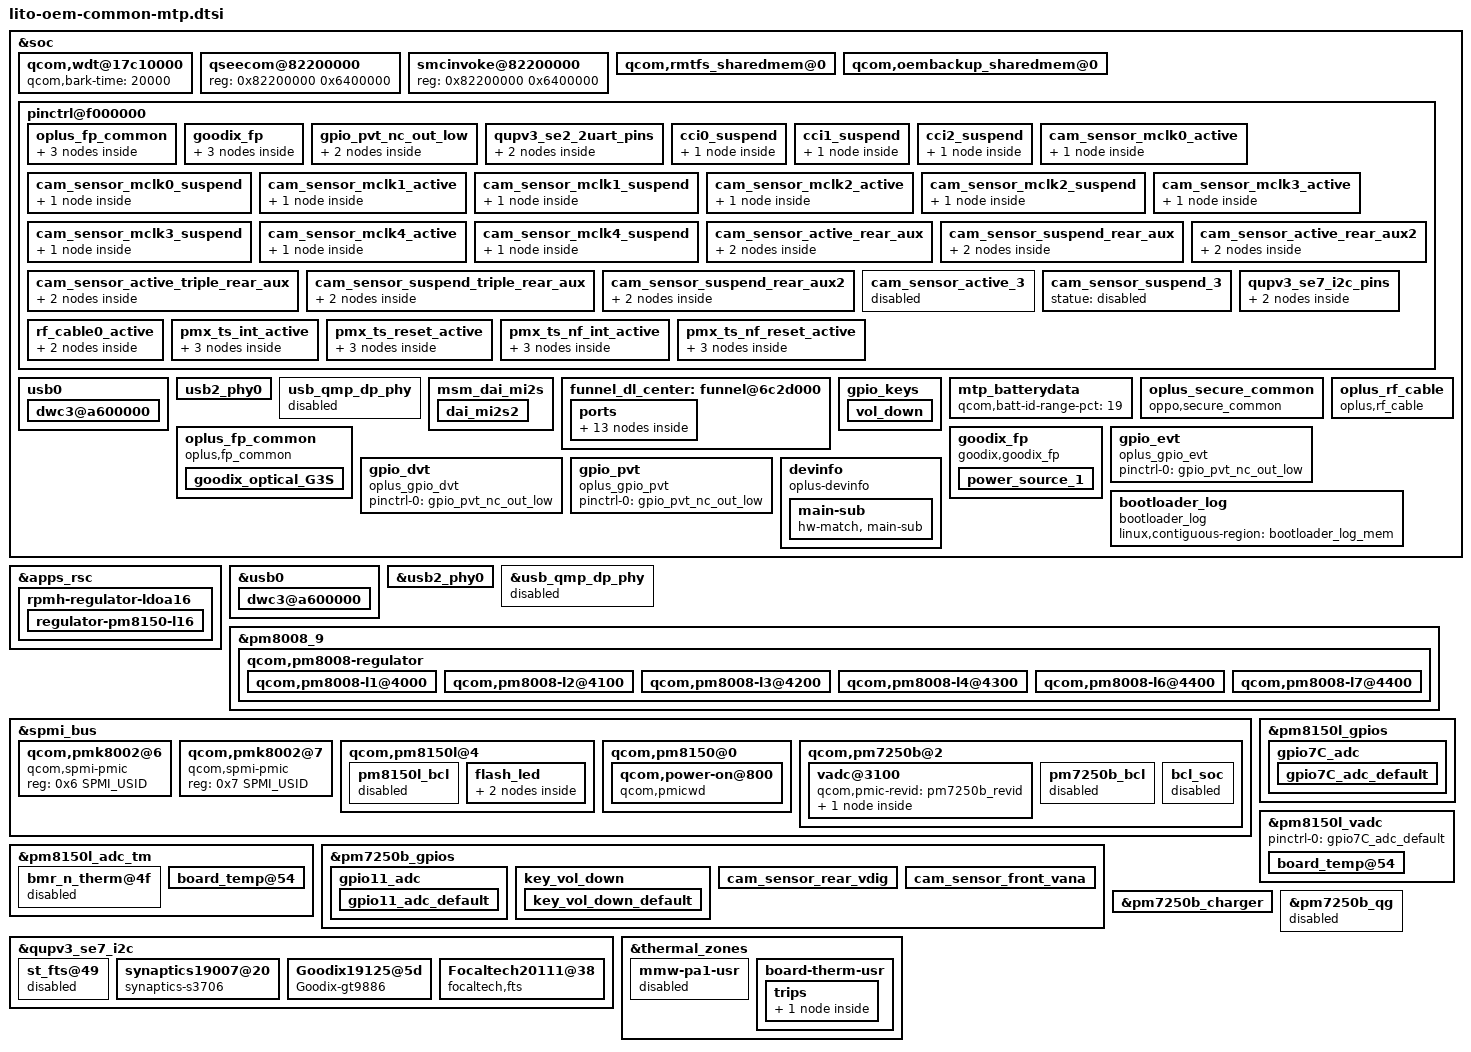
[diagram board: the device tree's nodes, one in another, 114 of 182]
// SPDX-License-Identifier: GPL-2.0-only
/*
 * Copyright (C) 2018-2020 Oplus. All rights reserved.
 */
#include <dt-bindings/msm/msm-bus-ids.h>
//#include "oplus_charge.dtsi"
#include "kunlun_camera/lito-camera-sensor-mtp.dtsi"
#include "display/lito-display.dtsi"

&soc {
        qcom,wdt@17c10000 {
               /*add for raising bark-time*/
               qcom,bark-time = <20000>;
        };
        qseecom@82200000 {
                //#ifndef OPLUS_FEATURE_FINGERPRINT
                //reg = <0x82200000 0x2200000>;
                //#else
                reg = <0x82200000 0x6400000>;
                //#endif /* OPLUS_FEATURE_FINGERPRINT */
        };

        smcinvoke@82200000 {
                //#ifndef OPLUS_FEATURE_FINGERPRINT
                //reg = <0x82200000 0x2200000>;
                //#else
                reg = <0x82200000 0x6400000>;
                //#endif /* OPLUS_FEATURE_FINGERPRINT */
        };

        qcom,rmtfs_sharedmem@0 {
                //#ifndef OPLUS_FEATURE_FINGERPRINT
                //reg = <0x0 0x200000>;
                //#else
                reg = <0x9ea00000 0x200000>;
                //#endif /* FEATURE_OPPO_NV_BACKUP */
                //#endif /* OPLUS_FEATURE_FINGERPRINT */

                //#ifdef VENDOR_EDIT
                //#ifdef FEATURE_OPPO_NV_BACKUP
                //add for oem share mem mapping virtual addr fail
                memory-region = <&uio_mem>;
                //#endif /* FEATURE_OPPO_NV_BACKUP */
                //#endif /* VENDOR_EDIT */
                qcom,guard-memory;
        };

        //#ifdef OPLUS_FEATURE_FINGERPRINT
        //#ifdef FEATURE_OPPO_NV_BACKUP
        //add for creating a shared memory with uio for nv backup and restore
        qcom,oembackup_sharedmem@0 {
                reg = <0x9ec00000 0x00100000>;
                memory-region = <&uio_oem>;
        };
        //#endif /* FEATURE_OPPO_NV_BACKUP */
        //#endif /* OPLUS_FEATURE_FINGERPRINT */

        pinctrl@f000000 {
        //#ifdef /*OPLUS_FEATURE_FINGERPRINT*/
        oplus_fp_common{
            gpio_id2_default: gpio_id2_default {
                mux {
                    pins = "gpio65";
                    function = "gpio";
                };
                config {
                    pins = "gpio65";
                    drive-strength = <2>;
                    bias-pull-up;
                    input-enable;
                };
            };
        };
        /*#ifdef OPLUS_FEATURE_FINGERPRINT Qijia.Zhou@Bsp.Fingerprint.Basic 2020-08-01 add for goodix fingerprint */
        goodix_fp{
            gpio_goodix_irq_default: gpio_goodix_irq_default {
                mux {
                    pins = "gpio112";
                    function = "gpio";
                };
                config {
                    pins = "gpio112";
                    drive-strength = <2>;
                    bias-disable;
                    input-enable;
                };
            };
        };
        //#endif /*OPLUS_FEATURE_FINGERPRINT*/

		gpio_pvt_nc_out_low: gpio_pvt_nc_out_low {
			mux {
				pins = "gpio48";
				function = "gpio";
			};

			config {
				pins = "gpio48";
				drive-strength = <2>;
				output-low;
			};

		};

                qupv3_se2_2uart_pins {
                        qupv3_se2_2uart_sleep {
                                config {
                                        input-enable;
                                        bias-disable;
                                        //#else
                                        ///bias-pull-down;
                                        //#endif
                                };
                        };
                };

                cci0_suspend {
                        config {
/*#ifdef VENDOR_EDIT */
                                //bias-pull-down; /* PULL DOWN */
                                bias-disable;
                                output-low;
/*endif*/
                        };
                };

                cci1_suspend {
                        config {
/*#ifdef VENDOR_EDIT */
                                //bias-pull-down; /* PULL DOWN */
                                bias-disable;
                                output-low;
/*endif*/
                        };
                };

                cci2_suspend {
                        config {
/*#ifdef VENDOR_EDIT */
                                //bias-pull-down; /* PULL DOWN */
                                bias-disable;
                                output-low;
/*endif*/
                        };
                };

                /* Camera GPIOs  CCI*/
                cam_sensor_mclk0_active {
                        config {
/*#ifdef VENDOR_EDIT */
                                drive-strength = <6>; /* 2 MA */
/*endif*/
                        };
                };

                cam_sensor_mclk0_suspend {
                        config {
/*#ifdef VENDOR_EDIT */
                                drive-strength = <6>; /* 2 MA */
/*endif*/
                        };
                };

                cam_sensor_mclk1_active {
                        config {
/*#ifdef VENDOR_EDIT */
                                drive-strength = <6>; /* 2 MA */
/*endif*/
                        };
                };

                cam_sensor_mclk1_suspend {
                        config {
/*#ifdef VENDOR_EDIT */
                                drive-strength = <6>; /* 2 MA */
/*endif*/
                        };
                };

                cam_sensor_mclk2_active {
                        config {
/*#ifdef VENDOR_EDIT */
                                drive-strength = <4>; /* 2 MA */
/*endif*/
                        };
                };

                cam_sensor_mclk2_suspend {
                        config {
/*#ifdef VENDOR_EDIT */
                                drive-strength = <4>; /* 2 MA */
/*endif*/
                        };
                };

                cam_sensor_mclk3_active {
                        config {
/*#ifdef VENDOR_EDIT */
                                drive-strength = <6>; /* 2 MA */
/*endif*/
                        };
                };

                cam_sensor_mclk3_suspend {
                        config {
/*#ifdef VENDOR_EDIT */
                                drive-strength = <6>; /* 2 MA */
/*endif*/
                        };
                };

                cam_sensor_mclk4_active {
                        config {
/*#ifdef VENDOR_EDIT */
                                drive-strength = <6>; /* 2 MA */
/*endif*/
                        };
                };

                cam_sensor_mclk4_suspend {
                        config {
/*#ifdef VENDOR_EDIT */
                                drive-strength = <6>; /* 2 MA */
/*endif*/
                        };
                };

                cam_sensor_active_rear_aux {
                        /* RESET REARAUX,DVDD ELDO */
                        mux {
                                pins = "gpio21";
                        };

                        config {
                                pins = "gpio21";
                        };
                };

                cam_sensor_suspend_rear_aux {
                        /* RESET REARAUX,DVDD ELDO */
                        mux {
                                pins = "gpio21";
                        };

                        config {
                                pins = "gpio21";
                        };
                };

                cam_sensor_active_triple_rear_aux {
                        mux {
                                pins = "gpio23";
                        };

                        config {
                                pins = "gpio23";
                        };
                };

                cam_sensor_suspend_triple_rear_aux {
                        mux {
                                pins = "gpio23";
                        };

                        config {
                                pins = "gpio23";
                        };
                };

                cam_sensor_active_rear_aux2 {
                        mux {
                                pins = "gpio29";
                        };

                        config {
                                pins = "gpio29";
                        };
                };

                cam_sensor_suspend_rear_aux2 {
                        mux {
                                pins = "gpio29";
                        };

                        config {
                                pins = "gpio29";
                        };
                };

                cam_sensor_active_3 {
                        status = "disabled";
                };

                cam_sensor_suspend_3 {
                        statue = "disabled";
                };

                /* SE 7 pin mappings */
                qupv3_se7_i2c_pins {
                        qupv3_se7_i2c_sleep {
                                config {
                                        //#ifdef VENDOR_EDIT
                                        //Zengpeng.Chen@BSP.TP.Function 2019-08-08 add for set i2c bus line as input
                                        input-enable;
                                        //#endif//VENDOR_EDIT
                                };
                        };
                };

		//#ifdef VENDOR_EDIT
		/* Fuchun.Liao@BSP.CHG.Basic 2018/11/27 modify for rf-cable */
		rf_cable0_active: rf_cable0_active {
			mux {
				pins = "gpio90";
				function = "gpio";
			};
			config {
				pins = "gpio90";
				drive-strength = <2>;
				input-enable;
				bias-pull-up;
			};
		};
		//#endif /* VENDOR_EDIT */ 

                //#ifdef VENDOR_EDIT
                pmx_ts_int_active {
                        ts_int_active: ts_int_active {
                                mux {
                                        pins = "gpio9";
                                        function = "gpio";
                                };

                                config {
                                        pins = "gpio9";
                                        drive-strength = <2>;
                                        bias-disable;
                                };
                        };
                };

                pmx_ts_reset_active {
                        ts_reset_active: ts_reset_active {
                                mux {
                                        pins = "gpio8";
                                        function = "gpio";
                                };

                                config {
                                        pins = "gpio8";
                                        drive-strength = <2>;
                                        bias-disable;
                                        output-low;
                                };
                        };
                };

                pmx_ts_nf_int_active {
                        ts_nf_int_active: ts_nf_int_active {
                                mux {
                                        pins = "gpio5";
                                        function = "gpio";
                                };

                                config {
                                        pins = "gpio5";
                                        drive-strength = <2>;
                                        bias-disable;
                                };
                        };
                };

                pmx_ts_nf_reset_active {
                        ts_nf_reset_active: ts_nf_reset_active {
                                mux {
                                        pins = "gpio4";
                                        function = "gpio";
                                };

                                config {
                                        pins = "gpio4";
                                        drive-strength = <2>;
                                        bias-disable;
                                        output-low;
                                };
                        };
                };
                //#endif
        };
};

&apps_rsc {
	rpmh-regulator-ldoa16 {
		regulator-pm8150-l16 {
			//#ifdef VENDOR_EDIT
			//LiPing-m@PSW.MM.Display.LCD 2018-10-21 Modity for lcd
			regulator-min-microvolt = <3000000>;
			qcom,init-voltage = <3000000>;
			//#endif
		};
	};
};

&soc {
        usb0 {
//#ifndef OPLUS_FEATRUE_CHG_BASIC
//Kun.Zhang@BSP.CHG.Basic  2019/11/22  Modify for mtp/otg speed 
                //qcom,core-clk-rate = <133333333>;
//#else
                qcom,core-clk-rate = <200000000>;
//#endif

                qcom,msm-bus,vectors-KBps =
                        /*  suspend vote */
                        <MSM_BUS_MASTER_USB3 MSM_BUS_SLAVE_EBI_CH0 0 0>,
                        <MSM_BUS_MASTER_USB3 MSM_BUS_SLAVE_IPA_CFG 0 0>,
                        <MSM_BUS_MASTER_AMPSS_M0 MSM_BUS_SLAVE_USB3 0 0>,

                        /*  nominal vote */
//#ifndef OPLUS_FEATRUE_CHG_BASIC
//Kun.Zhang@BSP.CHG.Basic  2019/11/22  Modify for mtp/otg speed 
                        //<MSM_BUS_MASTER_USB3
                                //MSM_BUS_SLAVE_EBI_CH0 1000000 2500000>,
                        //<MSM_BUS_MASTER_USB3 MSM_BUS_SLAVE_IPA_CFG 0 2400>,
                        //<MSM_BUS_MASTER_AMPSS_M0 MSM_BUS_SLAVE_USB3 0 40000>,
//#else
                        <MSM_BUS_MASTER_USB3
                                MSM_BUS_SLAVE_EBI_CH0 2500000 2500000>,
                        <MSM_BUS_MASTER_USB3 MSM_BUS_SLAVE_IPA_CFG 2400 2400>,
                        <MSM_BUS_MASTER_AMPSS_M0 MSM_BUS_SLAVE_USB3 40000 40000>,
//#endif

                        /*  svs vote */
//#ifndef OPLUS_FEATRUE_CHG_BASIC
//Kun.Zhang@BSP.CHG.Basic  2019/11/22  Modify for mtp/otg speed 
                        //<MSM_BUS_MASTER_USB3
                                //MSM_BUS_SLAVE_EBI_CH0 240000 700000>,
                        //<MSM_BUS_MASTER_USB3 MSM_BUS_SLAVE_IPA_CFG 0 2400>,
                        //<MSM_BUS_MASTER_AMPSS_M0 MSM_BUS_SLAVE_USB3 0 40000>,
//#else
                        <MSM_BUS_MASTER_USB3
                                MSM_BUS_SLAVE_EBI_CH0 2500000 2500000>,
                        <MSM_BUS_MASTER_USB3 MSM_BUS_SLAVE_IPA_CFG 2400 2400>,
                        <MSM_BUS_MASTER_AMPSS_M0 MSM_BUS_SLAVE_USB3 40000 40000>,
//#endif

                        /*  min vote */
                        <MSM_BUS_MASTER_USB3 MSM_BUS_SLAVE_EBI_CH0 1 1>,
                        <MSM_BUS_MASTER_USB3 MSM_BUS_SLAVE_IPA_CFG 1 1>,
                        <MSM_BUS_MASTER_AMPSS_M0 MSM_BUS_SLAVE_USB3 1 1>;

                dwc3@a600000 {
//#ifndef OPLUS_FEATRUE_CHG_BASIC
//Kun.Zhang@BSP.CHG.Basic  2019/09/25  Delete for usb 2.0
                        //usb-phy = <&usb2_phy0>, <&usb_qmp_dp_phy>;
//#else
                        usb-phy = <&usb2_phy0>, <&usb_nop_phy>;
//#endif

//#ifdef OPLUS_FEATRUE_CHG_BASIC
//Kun.Zhang@BSP.CHG.Basic  2019/11/22  add for mtp/otg speed 
                        xhci-imod-value = <160>;
                        qcom,pm-qos-latency= <62>;
//#endif

//#ifndef OPLUS_FEATRUE_CHG_BASIC
//Kun.Zhang@BSP.CHG.Basic  2019/09/25  Modify for usb 2.0
                        //maximum-speed = "super-speed";
//#else
                        maximum-speed = "high-speed";
//#endif
                };
        };

        usb2_phy0 {
//#ifndef OPLUS_FEATRUE_CHG_BASIC
//Kun.Zhang@BSP.CHG.Basic  2019/09/25  Delete for usb eye parameter
                //qcom,param-override-seq = <0x43 0x70>;
//#else
                qcom,param-override-seq = <0x07 0x6c
                                                                  0x0b 0x70
                                                                  0x04 0x74
                                                                  0x00 0x78>;
//#ifdef OPLUS_FEATRUE_CHG_BASIC
//Jacky.Zhuo@BSP.CHG.Basic  2020/04/27  Add for host mode eye diagram
                qcom,param-override-seq-host = <0x07 0x6c
                                                                  0x0b 0x70
                                                                  0x04 0x74
                                                                  0x00 0x78>;
//#endif
//#endif
        };

        usb_qmp_dp_phy {
//#ifndef OPLUS_FEATRUE_CHG_BASIC
//Kun.Zhang@BSP.CHG.Basic  2019/09/25  Modify for usb 2.0
                //status = "ok";
//#else
                status = "disabled";
//endif
        };
};

&usb0 {
//#ifndef OPLUS_FEATRUE_CHG_BASIC
//Kun.Zhang@BSP.CHG.Basic  2019/11/22  Modify for mtp/otg speed 
                //qcom,core-clk-rate = <133333333>;
//#else
                qcom,core-clk-rate = <200000000>;
//#endif

                qcom,msm-bus,vectors-KBps =
                        /*  suspend vote */
                        <MSM_BUS_MASTER_USB3 MSM_BUS_SLAVE_EBI_CH0 0 0>,
                        <MSM_BUS_MASTER_USB3 MSM_BUS_SLAVE_IPA_CFG 0 0>,
                        <MSM_BUS_MASTER_AMPSS_M0 MSM_BUS_SLAVE_USB3 0 0>,

                        /*  nominal vote */
//#ifndef OPLUS_FEATRUE_CHG_BASIC
//Kun.Zhang@BSP.CHG.Basic  2019/11/22  Modify for mtp/otg speed 
                        //<MSM_BUS_MASTER_USB3
                                //MSM_BUS_SLAVE_EBI_CH0 1000000 2500000>,
                        //<MSM_BUS_MASTER_USB3 MSM_BUS_SLAVE_IPA_CFG 0 2400>,
                        //<MSM_BUS_MASTER_AMPSS_M0 MSM_BUS_SLAVE_USB3 0 40000>,
//#else
                        <MSM_BUS_MASTER_USB3
                                MSM_BUS_SLAVE_EBI_CH0 2500000 2500000>,
                        <MSM_BUS_MASTER_USB3 MSM_BUS_SLAVE_IPA_CFG 2400 2400>,
                        <MSM_BUS_MASTER_AMPSS_M0 MSM_BUS_SLAVE_USB3 40000 40000>,
//#endif

                        /*  svs vote */
//#ifndef OPLUS_FEATRUE_CHG_BASIC
//Kun.Zhang@BSP.CHG.Basic  2019/11/22  Modify for mtp/otg speed 
                        //<MSM_BUS_MASTER_USB3
                                //MSM_BUS_SLAVE_EBI_CH0 240000 700000>,
                        //<MSM_BUS_MASTER_USB3 MSM_BUS_SLAVE_IPA_CFG 0 2400>,
                        //<MSM_BUS_MASTER_AMPSS_M0 MSM_BUS_SLAVE_USB3 0 40000>,
//#else
                        <MSM_BUS_MASTER_USB3
                                MSM_BUS_SLAVE_EBI_CH0 2500000 2500000>,
                        <MSM_BUS_MASTER_USB3 MSM_BUS_SLAVE_IPA_CFG 2400 2400>,
                        <MSM_BUS_MASTER_AMPSS_M0 MSM_BUS_SLAVE_USB3 40000 40000>,
//#endif

                        /*  min vote */
                        <MSM_BUS_MASTER_USB3 MSM_BUS_SLAVE_EBI_CH0 1 1>,
                        <MSM_BUS_MASTER_USB3 MSM_BUS_SLAVE_IPA_CFG 1 1>,
                        <MSM_BUS_MASTER_AMPSS_M0 MSM_BUS_SLAVE_USB3 1 1>;

                dwc3@a600000 {
//#ifndef OPLUS_FEATRUE_CHG_BASIC
//Kun.Zhang@BSP.CHG.Basic  2019/09/25  Delete for usb 2.0
                        //usb-phy = <&usb2_phy0>, <&usb_qmp_dp_phy>;
//#else
                        usb-phy = <&usb2_phy0>, <&usb_nop_phy>;
//#endif

//#ifdef OPLUS_FEATRUE_CHG_BASIC
//Kun.Zhang@BSP.CHG.Basic  2019/11/22  add for mtp/otg speed 
                        xhci-imod-value = <160>;
                        qcom,pm-qos-latency= <62>;
//#endif

//#ifndef OPLUS_FEATRUE_CHG_BASIC
//Kun.Zhang@BSP.CHG.Basic  2019/09/25  Modify for usb 2.0
                        //maximum-speed = "super-speed";
//#else
                        maximum-speed = "high-speed";
//#endif
                };
};
&usb2_phy0 {
//#ifndef OPLUS_FEATRUE_CHG_BASIC
//Kun.Zhang@BSP.CHG.Basic  2019/09/25  Delete for usb eye parameter
                //qcom,param-override-seq = <0x43 0x70>;
//#else
                qcom,param-override-seq = <0x07 0x6c
                                                                  0x0b 0x70
                                                                  0x04 0x74
                                                                  0x00 0x78>;
//#ifdef OPLUS_FEATRUE_CHG_BASIC
//Jacky.Zhuo@BSP.CHG.Basic  2020/04/27  Add for host mode eye diagram
                qcom,param-override-seq-host = <0x07 0x6c
                                                                  0x0b 0x70
                                                                  0x04 0x74
                                                                  0x00 0x78>;
//#endif
//#endif
};

&usb_qmp_dp_phy {
//#ifndef OPLUS_FEATRUE_CHG_BASIC
//Kun.Zhang@BSP.CHG.Basic  2019/09/25  Modify for usb 2.0
                //status = "ok";
//#else
                status = "disabled";
//endif
};
&soc {
	msm_dai_mi2s {
		dai_mi2s2 {
			qcom,msm-mi2s-rx-lines = <0>;
			qcom,msm-mi2s-tx-lines = <3>;
		};
	};
};

&soc {
	funnel_dl_center: funnel@6c2d000 {
		ports {
			port@1 {
				reg = <0>;
			};

			port@2 {
				reg = <0>;
			};

			port@3 {
				reg = <0>;
			};

			port@4 {
				reg = <0>;
			};

			port@5 {
				reg = <0>;
			};

			port@6 {
				reg = <0>;
			};

			port@7 {
				reg = <0>;
			};

			port@8 {
				reg = <0>;
			};

			port@9 {
				reg = <0>;
			};

			port@10 {
				reg = <0>;
			};

			port@11 {
				reg = <0>;
			};

			port@12 {
				reg = <0>;
			};

			port@13 {
				reg = <0>;
			};
		};
	};
};

&pm8008_9 {
	qcom,pm8008-regulator {
		vdd_l5-supply = <&S5A>;
		vdd_l6-supply = <&BOB>;
		vdd_l7-supply = <&BOB>;

		qcom,pm8008-l1@4000 {
			reg =  /bits/ 16 <0x4000>;
		/*#ifdef VENDOR_EDIT */
		        regulator-min-microvolt = <950000>;
		        regulator-max-microvolt = <1150000>;
		        qcom,min-dropout-voltage = <100000>;
		/*endif */
		};

		qcom,pm8008-l2@4100 {
			reg =  /bits/ 16 <0x4100>;
		/*#ifdef VENDOR_EDIT */
		        regulator-min-microvolt = <1200000>;
		        regulator-max-microvolt = <1200000>;
		        qcom,min-dropout-voltage = <100000>;
		/*endif */
		};

		qcom,pm8008-l3@4200 {
			reg =  /bits/ 16 <0x4200>;
		        regulator-min-microvolt = <2800000>;
		        regulator-max-microvolt = <2800000>;
		/*#ifdef VENDOR_EDIT */
		        //qcom,min-dropout-voltage = <136000>;
		/*endif */
		};

		qcom,pm8008-l4@4300 {
			reg =  /bits/ 16 <0x4300>;
		/*#ifdef VENDOR_EDIT */
		        regulator-max-microvolt = <2800000>;
		        //qcom,min-dropout-voltage = <160000>;
		/*endif */
		};

		qcom,pm8008-l6@4400 {
			reg =  /bits/ 16 <0x4500>;
		/*#ifdef VENDOR_EDIT */
		        regulator-min-microvolt = <2800000>;
		        regulator-max-microvolt = <2800000>;
		        //qcom,min-dropout-voltage = <184000>;
		/*endif */
		};

		qcom,pm8008-l7@4400 {
			reg =  /bits/ 16 <0x4600>;
		/*#ifdef VENDOR_EDIT */
		        regulator-min-microvolt = <2900000>;
		        regulator-max-microvolt = <2900000>;
		        //qcom,min-dropout-voltage = <200000>;
		/*endif */
		};
	};
};

&spmi_bus {
	/*Add spmi node for clk pmic PMK8002 */
	qcom,pmk8002@6 {
		compatible ="qcom,spmi-pmic";
		reg = <0x6 SPMI_USID>;
		#address-cells = <2>;
		#size-cells = <0>;
	};

	qcom,pmk8002@7 {
	compatible ="qcom,spmi-pmic";
		reg = <0x7 SPMI_USID>;
		#address-cells = <2>;
		#size-cells = <0>;
	};

	qcom,pm8150l@4 {
		pm8150l_bcl {
//#ifdef VENDOR_EDIT
//Kun.Zhang@BSP.CHG.Basic  2019/12/27  Modify for disable bcl 
			status = "disabled";
//#endif
		};

		flash_led {
			pm8150l_flash2 {
				/*#ifdef VENDOR_EDIT */
				status = "ok";
				/*endif */
			};

			pm8150l_torch2 {
				/*#ifdef VENDOR_EDIT */
				status = "ok";
				/*endif */
			};
		};
	};
	qcom,pm8150@0 {
		qcom,power-on@800
		{
			//#ifdef CONFIG_OPLUS_FEATURE_QCOM_PMICWD
			qcom,pmicwd;
			//#endif
		};
	};
};

&spmi_bus {
        qcom,pm7250b@2 {
                vadc@3100 {
                        //#ifdef VENDOR_EDIT
                        qcom,pmic-revid = <&pm7250b_revid>;
                        //#endif
			board_id {
				reg = <ADC_GPIO1>;
				label = "board_id_vdata";
				qcom,ratiometric;
				qcom,pre-scaling = <1 1>;
			}; 
                };

                pm7250b_bcl {
//#ifdef VENDOR_EDIT
//Kun.Zhang@BSP.CHG.Basic  2019/12/27  Modify for disable bcl 
                        status = "disabled";
//#endif
                };

                bcl_soc {
//#ifdef VENDOR_EDIT
//Kun.Zhang@BSP.CHG.Basic  2019/12/27  Modify for disable bcl 
                        status = "disabled";
//#endif
                };
        };
};

&soc {
	gpio_keys {
		//#ifdef VENDOR_EDIT
		//Fei.Mo@BSP.group 2018-09-01 Modity for vol key
		pinctrl-0 = <&key_vol_up_default &key_vol_down_default>;
		//#endif

		//#ifdef VENDOR_EDIT
		//Fei.Mo@BSP.group 2018-09-01 Add for vol key
		vol_down {
			label = "volume_down";
			gpios = <&pm7250b_gpios  3 GPIO_ACTIVE_LOW>;
			linux,input-type = <1>;
			linux,code = <KEY_VOLUMEDOWN>;
			gpio-key,wakeup;
			debounce-interval = <15>;
			linux,can-disable;
		};
		//#endif
	};

        mtp_batterydata {
//#ifndef VENDOR_EDIT
//Yichun.Chen@BSP.CHG.Basic  2018/05/10  Delete for use oppo battery
//              qcom,batt-id-range-pct = <15>;
//#else
        qcom,batt-id-range-pct = <19>;
//#endif
        };

        // #ifdef OPLUS_FEATURE_SECURITY_COMMON
        /* Ping.Liu@Bsp.Fingerprint.Secure 2019-10-16 add for secure proc */
        oplus_secure_common {
                compatible = "oppo,secure_common";
        };
        //#endif /* OPLUS_FEATURE_SECURITY_COMMON */

    //#ifdef OPLUS_FEATURE_FINGERPRINT /*OPLUS_FEATURE_FINGERPRINT*/
    oplus_fp_common {
        compatible = "oplus,fp_common";
        oplus,fp_gpio_num = <1>; /* the gpio number of fingerprint id used */
        oplus,fp_gpio_0 = <&tlmm 65 0x0>;
        pinctrl-names = "default";
        pinctrl-0 = <&gpio_id2_default>;
        goodix_optical_G3S {
            oplus,fp-id = <1>; /* fp id mapping table */
            vendor-chip = <11>; /* please refer to the struct fp_vendor_t in oppo_fp_commmon.n */
            eng-menu = "-1,-1"; /* represents SNR, inclination test item in engineer menu, and 0/1 means off/on */
            chip-name = "G_OPTICAL_G3S";  /* /proc/fp_id, will be displayed in engineer menu  */
        };
    };

    goodix_fp {
        status = "ok";
        compatible = "goodix,goodix_fp";
        interrupt-parent = <&tlmm>;
        interrupts = <112 0>;
        power-mode = <1> ; /*please refer to the struct fp_power_mode_t in oppo_fp_commmon.n ,0: power mode not set, 1: ldo power, 2: gpio power, 3: auto power */
        ldo-supply = <&pm8150a_l9>; // pm660l_l5 for goodix_fp
        ldo-config = <3300000 3300000 150000>;
        gpio-power = <&pm8150_gpios 7 GPIO_ACTIVE_LOW>;
        goodix,gpio_irq = <&tlmm 112 0x1>;
        goodix,gpio_reset = <&tlmm 63 0x0>;
        pinctrl-names = "default";
        pinctrl-0 = <&gpio_goodix_irq_default>;
        notify_tpinfo_flag = <1>;
        power-num = <1> ;
        power_source_1 {
            power-mode = <1>;   /* 1 = ldo power, refer to oplus_fp_common.h*/
            power-name = "ldo";
            power-config = "ldo-config";
            delay-time = <0>;
        };
    };
    //#endif /*OPLUS_FEATURE_FINGERPRINT*/

	gpio_evt {
		status = "ok";
		compatible = "oplus_gpio_evt";
		pinctrl-names = "default";
		pinctrl-0 = <&gpio_pvt_nc_out_low>;
	};
	//#endif
	gpio_dvt {
		status = "ok";
		compatible = "oplus_gpio_dvt";
		pinctrl-names = "default";
		pinctrl-0 = <&gpio_pvt_nc_out_low>;
	};
	gpio_pvt {
		status = "ok";
		compatible = "oplus_gpio_pvt";
		pinctrl-names = "default";
		pinctrl-0 = <&gpio_pvt_nc_out_low>;
	};

	devinfo {
		compatible = "oplus-devinfo";

		io-channels= <&pm7250b_vadc ADC_GPIO1>;
		io-channel-names= "vph_pwr_voltage_sub";
		pinctrl-names = "default";
		pinctrl-0 = <&gpio11_adc_default>;

		main-sub {
			compatible = "hw-match, main-sub";
			use_pmic_adc;
			adc_ranges = <0 80
						81 180
						181 300
						301 420
						421 550
						551 650
						651 760
						761 850
						851 850
						951 1050
						1051 1150
						1151 1300>;
			aboard-patterns = <0 0 1>;

			/*main board*/
			match-projects = <20111 20113 20251 20811>;
		};
	};

	/* Fuchun.Liao@BSP.CHG.Basic 2018/11/26 modify for oplus rf cable monitor */
        oplus_rf_cable {
                compatible = "oplus,rf_cable";
                interrupt-parent = <&tlmm>;
                rf_cable_support_num = <1>;
                rf,cable0-gpio = <&tlmm 90 0>;
                rf,cable-support-timer = <0>;
                pinctrl-names = "rf_cable_active";
                pinctrl-0 = <&rf_cable0_active>;
        };
	//#endif /* VENDOR_EDIT */
};

&pm8150l_gpios {
/*#ifdef OPLUS_FEATURE_BOARD_TEMP */
        gpio7C_adc {
			gpio7C_adc_default: gpio7C_adc_default {
			pins = "gpio7"; /* GPIO07 */
			function = "normal"; /* normal */
			bias-high-impedance; /* DISABLE GPIO07 for ADC*/
			bias-disable;
		};
	};

/*#endif*/
};

&pm8150l_vadc {
/*#ifdef OPLUS_FEATURE_BOARD_TEMP */
	pinctrl-names = "default";
	pinctrl-0 = <&gpio7C_adc_default>;
/*#endif*/

/*#ifdef OPLUS_FEATURE_BOARD_TEMP */
	board_temp@54 {
		reg = <ADC_GPIO3_PU2>;
		label = "board_temp";
		qcom,ratiometric;
		qcom,hw-settle-time = <200>;
		qcom,pre-scaling = <1 1>;
	};
/*#endif*/
};

&pm8150l_adc_tm {
	io-channels = <&pm8150l_vadc ADC_AMUX_THM1_PU2>,
			<&pm8150l_vadc ADC_AMUX_THM2_PU2>,
			<&pm8150l_vadc ADC_AMUX_THM3_PU2>,
/*#ifdef OPLUS_FEATURE_BOARD_TEMP */
			<&pm8150l_vadc ADC_GPIO3_PU2>;
/*#endif*/

/*#ifndef OPLUS_FEATURE_BOARD_TEMP */
	bmr_n_therm@4f {
		status = "disabled";
	};
/*#endif*/
/*#ifdef OPLUS_FEATURE_BOARD_TEMP */
	board_temp@54 {
		reg = <ADC_GPIO3_PU2>; //PM7150A_GPIO7
		qcom,ratiometric;
		qcom,hw-settle-time = <200>;
	};
/*#endif*/
};

&pm7250b_gpios{
//#ifdef VENDOR_EDIT
//tongfeng.huang@BSP.CHG.Basic  2019/11/20  add for board-id adc
        gpio11_adc {
        gpio11_adc_default: gpio11_adc_default {
        pins = "gpio11"; /* GPIO 11 */
        function = "normal"; /* normal */
        bias-high-impedance; /* DISABLE GPIO11 for ADC*/
        };
    };
//#endif

	//#ifdef VENDOR_EDIT
	//Fei.Mo@BSP.group 2018-09-01 Add for vol key
	key_vol_down {
		key_vol_down_default: key_vol_down_default {
			pins = "gpio3";
			function = "normal";
			input-enable;
			bias-pull-up;
			power-source = <0>;
		};
	};
	//#endif

/*#ifdef VENDOR_EDIT */
	cam_sensor_rear_vdig: cam_sensor_rear_vdig {
		pins = "gpio10";
		function = "normal";
		power-source = <0>;
		drive-push-pull;
		output-low;
	};
	cam_sensor_front_vana: cam_sensor_front_vana {
		pins = "gpio12";
		function = "normal";
		power-source = <0>;
		drive-push-pull;
		output-low;
	};
/*
	cam_sensor_rear2_vana: cam_sensor_rear2_vana {
		pins = "gpio2";
		function = "normal";
		power-source = <0>;
		output-low;
	};

*/
/*endif */
};

&pm7250b_charger {
        io-channels = <&pm7250b_vadc ADC_USB_IN_V_16>,
                      <&pm7250b_vadc ADC_USB_IN_I>,
                      <&pm7250b_vadc ADC_CHG_TEMP>,
                          <&pm7250b_vadc ADC_GPIO3>,
                          <&pm7250b_vadc ADC_AMUX_THM4_PU2>,
//#endif
                      <&pm7250b_vadc ADC_DIE_TEMP>,
                      <&pm7250b_vadc ADC_AMUX_THM3_PU2>,
                      <&pm7250b_vadc ADC_SBUx>,
                      <&pm7250b_vadc ADC_VPH_PWR>,
                      <&pm7250b_vadc ADC_AMUX_THM1_PU2>;
        io-channel-names = "usb_in_voltage",
                           "usb_in_current",
                           "chg_temp",
                           "chgID_voltage_adc",
                           "usb_temp_l",
//#endif
                           "die_temp",
                           "usb_temp_r",
//#else
                           //"conn_temp",
//#endif
                           "sbux_res",
                           "vph_voltage",
                           "skin_temp";
};

&pm7250b_qg {
        status = "disabled";
//#else
        //status = "ok";
//#endif
};

&qupv3_se7_i2c {
        //#ifdef VENDOR_EDIT
        //wangkun@BSP.group 2019-06-28 add for enable i2c_7
	st_fts@49 {
		status = "disabled";
	};

        synaptics19007@20 {
                compatible = "synaptics-s3706";
                reg = <0x20>;
                chip-name = "S3706";

                /* Interrupt && Irq-gpio */
                interrupt-parent = <&tlmm>;
                interrupts = <9 0x2008>;

                /* Power Config */
                vdd_2v8-supply = <&pm8150_l13>;
                vcc_1v8-supply = <&pm8150a_l1>;
                vdd_2v8_volt = <3000000>;

                /* Other HW Resource */
                irq-gpio = <&tlmm 9 0x2008>;
                reset-gpio = <&tlmm 8 0x1>;
                pinctrl-names = "default";
                pinctrl-0 = <&ts_int_active &ts_reset_active>;

                touchpanel,max-num-support = <10>;
                touchpanel,tx-rx-num = <16 34>;
                touchpanel,panel-coords = <1080 2340>;
                touchpanel,display-coords = <1080 2340>;
                touchpanel,touchmajor-limit = <0 54>;

                /* SW Support Feature Control */
                black_gesture_support;
                fw_edge_limit_support;
                fw_corner_limit_support;
                pressure_report_support;
                //spurious_fingerprint_support;
                charger_pump_support;
                game_switch_support;
                face_detect_support;
                smart_gesture_support;
                fw_update_app_support;
                fingerprint_underscreen_support;
                rt155_fdreplace_rt59_support;
                report_120hz_support;
                /*
                 *Virtual Key Config:
                 *1:touchpanel,button-type: <virtualkey_type  supportted_button-map>
                 *virtualkey_type:
                 *Type 1: using board_properties
                 *Type 2: using same IC (button zone&& touch zone are seprate)
                 *Type 3: using diffrent IC (button zone&& touch zone are seprate)
                 *Type 4: No need of virtual key process
                 *supportted_button-map:select|menu|home|back
                 *
                 *2:touchpanel,button-map
                 *type (X1,Y1)(X2,Y2)(X3,Y3)(Width_X,Hight_Y)--Only when button-type is 0
                 */
                touchpanel,button-type = <4>;
                touchpanel.button-TRx = <0 0>;
        };
        //#endif

        //#ifdef VENDOR_EDIT
        //Zengpeng.Chen@BSP.TP.Function 2019-08-25 add for enable Goodix touch device
        Goodix19125@5d {
                compatible = "Goodix-gt9886";
                reg = <0x5d>;
                chip-name = "GT9886";

                /* Interrupt && Irq-gpio */
                interrupt-parent = <&tlmm>;
                interrupts = <9 0x2002>;

                /* Power Config */
                vdd_2v8-supply = <&pm8150_l13>;
                vcc_1v8-supply = <&pm8150a_l1>;
                vdd_2v8_volt = <3100000>;

                /* Other HW Resource */
                irq-gpio = <&tlmm 9 0x2002>;
                reset-gpio = <&tlmm 8 0x1>;
                pinctrl-names = "default";
                pinctrl-0 = <&ts_int_active &ts_reset_active>;

                vid_len = <2>;
                tp_type = <8>;
                // type of tp_dev ,TP-SAMSUNG = 8;
                platform_support_project = <20111 20113 20251 20811>;
                platform_support_project_dir = <19015 19015 19015 19015>;
                platform_support_project_commandline = "oppo19015samsung", "oppo19015samsung", "oppo19015samsung", "oppo19015samsung";

                touchpanel,max-num-support = <10>;
                touchpanel,tx-rx-num = <16 34>;
                touchpanel,panel-coords = <1080 2400>;
                touchpanel,display-coords = <1080 2400>;
                touchpanel,touchmajor-limit = <0 54>;

                /* SW Support Feature Control */
                register-is-16bit;
                black_gesture_support;
                fw_edge_limit_support;
                pressure_report_support;
                charger_pump_support;
                game_switch_support;
                smart_gesture_support;
                fw_update_app_support;
                fingerprint_underscreen_support;
                esd_handle_support;
                //new_set_irq_wake_support;
                //single_tap_support;
                /*
                 *Virtual Key Config:
                 *1:touchpanel,button-type: <virtualkey_type  supportted_button-map>
                 *virtualkey_type:
                 *Type 1: using board_properties
                 *Type 2: using same IC (button zone&& touch zone are seprate)
                 *Type 3: using diffrent IC (button zone&& touch zone are seprate)
                 *Type 4: No need of virtual key process
                 *supportted_button-map:select|menu|home|back
                 *
                 *2:touchpanel,button-map
                 *type (X1,Y1)(X2,Y2)(X3,Y3)(Width_X,Hight_Y)--Only when button-type is 0
                 */
                touchpanel,button-type = <4>;
                touchpanel.button-TRx = <0 0>;
        };

	Focaltech20111@38 {
		compatible = "focaltech,fts";
		reg = <0x38>;
		chip-name = "FT3518";

		/* Interrupt && Irq-gpio */
		interrupt-parent = <&tlmm>;
		interrupts = <9 0x2002>;

		/* Power Config */
		vdd_2v8-supply = <&pm8150_l13>;
		vcc_1v8-supply = <&pm8150a_l1>;
		vdd_2v8_volt = <3100000>;

		/* Other HW Resource */
		irq-gpio = <&tlmm 9 0x2002>;
		reset-gpio = <&tlmm 8 0x1>;
		pinctrl-names = "default";
		pinctrl-0 = <&ts_int_active &ts_reset_active>;

		vid_len = <2>;
		tp_type = <8>;
		// type of tp_dev ,TP-SAMSUNG = 8;
		platform_support_project = <20111 20113 20251 20811>;
		platform_support_project_dir = <20111 20111 20111 20811>;
		platform_support_project_commandline = "oppo20111samsung", "oppo20111samsung", "oppo20111samsung", "oppo20111samsung";
		platform_support_project_external_name = "BD368", "BD368", "BD368", "BD368";

		touchpanel,max-num-support = <10>;
		touchpanel,tx-rx-num = <16 34>;
		touchpanel,panel-coords = <4320 9600>;
		touchpanel,display-coords = <1080 2400>;
		touchpanel,touchmajor-limit = <0 216>;
		touchpanel,report-rate = <120 180>;
		touchpanel,smooth-level = <255 2 32 64 96 128>;
		touchpanel,sensitive-level = <255 20 14 10 6 0>;
		touchpanel,single-optimized-time = <8>;

		prevention,dead_area_width = <20 20>;
		prevention,condition_area_width = <60 60 160 160>;
		prevention,eli_area_width = <240 1000 1200 240>;

		/* SW Support Feature Control */
		black_gesture_support;
		fw_edge_limit_support;
		pressure_report_support;
		charger_pump_support;
		game_switch_support;
		smart_gesture_support;
		fw_update_app_support;
		fingerprint_underscreen_support;
		headset_pump_support;
		irq_need_dev_resume_ok;
		health_monitor_v2_support;
		high_resolution_support;
		//esd_handle_support;
		/*
		 *Virtual Key Config:
		 *1:touchpanel,button-type: <virtualkey_type  supportted_button-map>
		 *virtualkey_type:
		 *Type 1: using board_properties
		 *Type 2: using same IC (button zone&& touch zone are seprate)
		 *Type 3: using diffrent IC (button zone&& touch zone are seprate)
		 *Type 4: No need of virtual key process
		 *supportted_button-map:select|menu|home|back
		 *
		 *2:touchpanel,button-map
		 *type (X1,Y1)(X2,Y2)(X3,Y3)(Width_X,Hight_Y)--Only when button-type is 0
		 */
		touchpanel,button-type = <4>;
		touchpanel.button-TRx = <0 0>;
	};
        //#endif
};

&thermal_zones {
/*#ifndef OPLUS_FEATURE_BOARD_TEMP */
	mmw-pa1-usr {
		status="disabled";
	};
/*#endif*/
/*#ifdef OPLUS_FEATURE_BOARD_TEMP */

	board-therm-usr {
		polling-delay-passive = <0>;
		polling-delay = <0>;
		thermal-governor = "user_space";
		thermal-sensors =  <&pm8150l_adc_tm ADC_GPIO3_PU2>;
		wake-capable-sensor;
		trips {
			active-config0 {
				temperature = <125000>;
				hysteresis = <1000>;
				type = "passive";
			};
		};
	};
/*#endif*/
};

&soc {

	bootloader_log {
		compatible = "bootloader_log";
		linux,contiguous-region = <&bootloader_log_mem>;
	};
};
